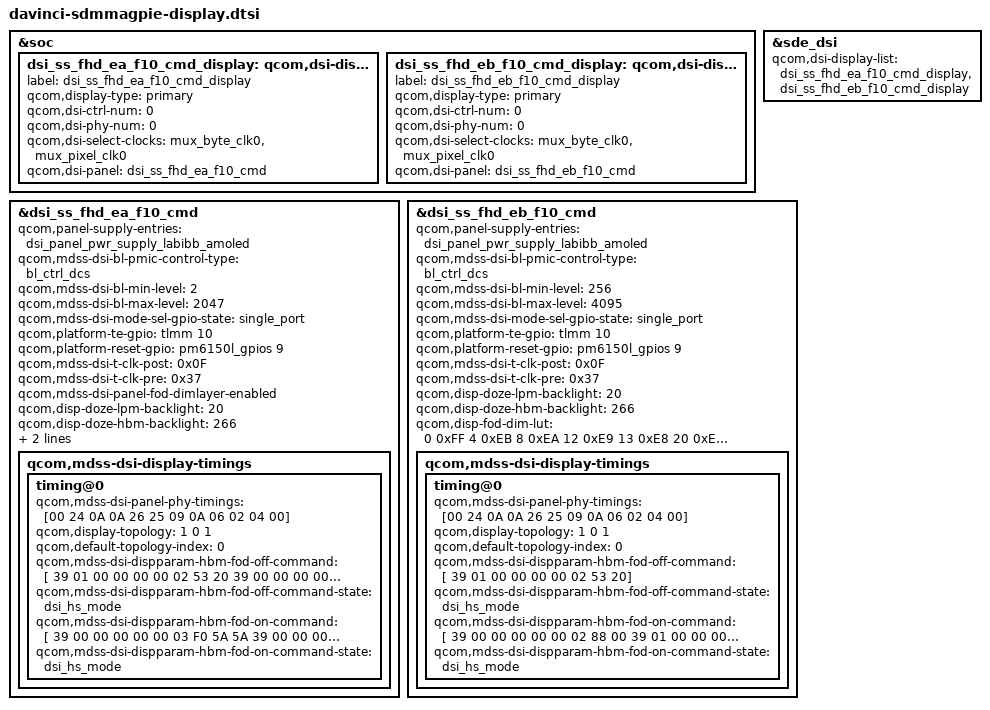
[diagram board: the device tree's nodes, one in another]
/*
 * Copyright (C) 2020 The LineageOS Project
 *
 * this file is for attribution only of davinci
 * And public attribution of Xiaomi platforms (like F10 and so)
 */
 
#include "../common/xiaomi-sdmmagpie-display.dtsi"

#include "display/dsi-panel-ss-fhd-ea-f10-cmd.dtsi"
#include "display/dsi-panel-ss-fhd-eb-f10-cmd.dtsi"

&soc {
    dsi_ss_fhd_ea_f10_cmd_display: qcom,dsi-display@22 {
        label = "dsi_ss_fhd_ea_f10_cmd_display";
        qcom,display-type = "primary";

        qcom,dsi-ctrl-num = <0>;
        qcom,dsi-phy-num = <0>;
        qcom,dsi-select-clocks = "mux_byte_clk0", "mux_pixel_clk0";
        qcom,dsi-panel = <&dsi_ss_fhd_ea_f10_cmd>;
    };

    dsi_ss_fhd_eb_f10_cmd_display: qcom,dsi-display@23 {

        label = "dsi_ss_fhd_eb_f10_cmd_display";
        qcom,display-type = "primary";

        qcom,dsi-ctrl-num = <0>;
        qcom,dsi-phy-num = <0>;
        qcom,dsi-select-clocks = "mux_byte_clk0", "mux_pixel_clk0";

        qcom,dsi-panel = <&dsi_ss_fhd_eb_f10_cmd>;
    };
};

&sde_dsi {
    qcom,dsi-display-list =
        <&dsi_ss_fhd_ea_f10_cmd_display
        &dsi_ss_fhd_eb_f10_cmd_display>;
};

&dsi_ss_fhd_ea_f10_cmd {
    qcom,panel-supply-entries = <&dsi_panel_pwr_supply_labibb_amoled>;
    qcom,mdss-dsi-bl-pmic-control-type = "bl_ctrl_dcs";
    qcom,mdss-dsi-bl-min-level = <2>;
    qcom,mdss-dsi-bl-max-level = <2047>;
    qcom,mdss-dsi-mode-sel-gpio-state = "single_port";
    qcom,platform-te-gpio = <&tlmm 10 0>;
    qcom,platform-reset-gpio = <&pm6150l_gpios 9 0>;

    qcom,mdss-dsi-t-clk-post = <0x0F>;
    qcom,mdss-dsi-t-clk-pre = <0x37>;

    qcom,mdss-dsi-panel-fod-dimlayer-enabled;

    qcom,disp-doze-lpm-backlight = <20>;
    qcom,disp-doze-hbm-backlight = <266>;

    qcom,disp-fod-dim-lut = <
      /* brightness, alpha */
      0 0xFF
      4 0xEB
      8 0xEA
      12  0xE9
      13  0xE8
      20  0xE5
      24  0xE3
      30  0xE0
      68  0xD0
      133 0xC0
      218 0xB0
      328 0xA0
      486 0x90
      642 0x80
      832 0x70
      1043  0x60
      1267  0x50
      1500  0x40
      1770  0x30
      2000  0x24
      2047  0x21
    >;

    qcom,mdss-dsi-display-timings {
        timing@0{
            qcom,mdss-dsi-panel-phy-timings = [00 24 0A 0A 26 25 09
                0A 06 02 04 00];
            qcom,display-topology = <1 0 1>;
            qcom,default-topology-index = <0>;
            qcom,mdss-dsi-dispparam-hbm-fod-off-command = [
              39 01 00 00 00 00 02 53 20
              39 00 00 00 00 00 03 F0 5A 5A
              39 00 00 00 00 00 03 B7 01 4B
              39 00 00 00 00 00 02 B0 03
              39 00 00 00 00 00 02 B7 49
              39 00 00 00 00 00 02 B0 07
              39 00 00 00 00 00 02 B7 11
              39 01 00 00 01 00 03 F0 A5 A5];
            qcom,mdss-dsi-dispparam-hbm-fod-off-command-state = "dsi_hs_mode";
            qcom,mdss-dsi-dispparam-hbm-fod-on-command = [
              39 00 00 00 00 00 03 F0 5A 5A
              39 00 00 00 00 00 02 B0 03
              39 00 00 00 00 00 02 B7 C9
              39 00 00 00 00 00 02 B0 07
              39 00 00 00 00 00 02 B7 11
              39 00 00 00 00 00 03 F0 A5 A5
              39 01 00 00 01 00 02 53 E0
              39 00 00 00 00 00 03 F0 5A 5A
              39 00 00 00 00 00 03 B7 01 43
              39 01 00 00 01 00 03 F0 A5 A5];
            qcom,mdss-dsi-dispparam-hbm-fod-on-command-state = "dsi_hs_mode";
        };
    };
};

&dsi_ss_fhd_eb_f10_cmd {
    qcom,panel-supply-entries = <&dsi_panel_pwr_supply_labibb_amoled>;
    qcom,mdss-dsi-bl-pmic-control-type = "bl_ctrl_dcs";
    qcom,mdss-dsi-bl-min-level = <256>;
    qcom,mdss-dsi-bl-max-level = <4095>;
    qcom,mdss-dsi-mode-sel-gpio-state = "single_port";
    qcom,platform-te-gpio = <&tlmm 10 0>;
    qcom,platform-reset-gpio = <&pm6150l_gpios 9 0>;

    qcom,mdss-dsi-t-clk-post = <0x0F>;
    qcom,mdss-dsi-t-clk-pre = <0x37>;

    qcom,disp-doze-lpm-backlight = <20>;
    qcom,disp-doze-hbm-backlight = <266>;

    qcom,disp-fod-dim-lut = <
      /* brightness, alpha */
      0 0xFF
      4 0xEB
      8 0xEA
      12  0xE9
      13  0xE8
      20  0xE5
      24  0xE3
      30  0xE0
      68  0xD0
      133 0xC0
      218 0xB0
      328 0xA0
      486 0x90
      642 0x80
      832 0x70
      1043  0x60
      1267  0x50
      1500  0x40
      1770  0x30
      2000  0x24
      2047  0x21
    >;

    qcom,mdss-dsi-display-timings {
        timing@0{
            qcom,mdss-dsi-panel-phy-timings = [00 24 0A 0A 26 25 09
                0A 06 02 04 00];
            qcom,display-topology = <1 0 1>;
            qcom,default-topology-index = <0>;
            qcom,mdss-dsi-dispparam-hbm-fod-off-command = [
              39 01 00 00 00 00 02 53 20];
            qcom,mdss-dsi-dispparam-hbm-fod-off-command-state = "dsi_hs_mode";
            qcom,mdss-dsi-dispparam-hbm-fod-on-command = [
              39 00 00 00 00 00 02 88 00
              39 01 00 00 00 00 02 53 E0];
            qcom,mdss-dsi-dispparam-hbm-fod-on-command-state = "dsi_hs_mode";
        };
    };
};

